# CH32F103xx register map
Vendor: WCH Ltd.; File version: 1.0
Registers are 32-bit, read-write, reset 0x0 unless marked. A register's access mark holds for its fields unless they carry their own. Offsets are from the block's base; [hi:lo] are bit positions.

## RCC — Reset and clock control
Base 0x40021000
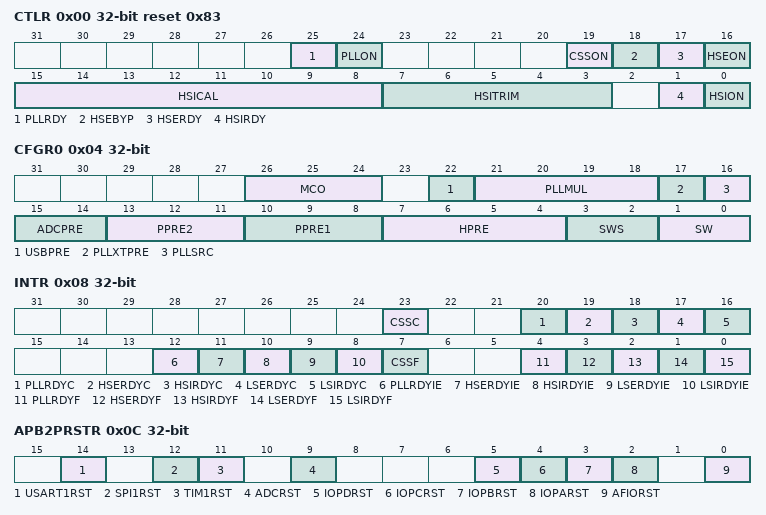
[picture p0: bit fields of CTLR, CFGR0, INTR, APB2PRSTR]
0x00 CTLR access per field reset 0x83 — Clock control register
  [25] PLLRDY ro — PLL clock ready flag
  [24] PLLON rw — PLL enable
  [19] CSSON rw — Clock Security System enable
  [18] HSEBYP rw — External High Speed clock Bypass
  [17] HSERDY ro — External High Speed clock ready flag
  [16] HSEON rw — External High Speed clock enable
  [15:8] HSICAL ro — Internal High Speed clock Calibration
  [7:3] HSITRIM rw — Internal High Speed clock trimming
  [1] HSIRDY ro — Internal High Speed clock ready flag
  [0] HSION rw — Internal High Speed clock enable
0x04 CFGR0 access per field — Clock configuration register (RCC_CFGR0)
  [26:24] MCO rw — Microcontroller clock output
  [22] USBPRE rw — USB prescaler
  [21:18] PLLMUL rw — PLL Multiplication Factor
  [17] PLLXTPRE rw — HSE divider for PLL entry
  [16] PLLSRC rw — PLL entry clock source
  [15:14] ADCPRE rw — ADC prescaler
  [13:11] PPRE2 rw — APB High speed prescaler (APB2)
  [10:8] PPRE1 rw — APB Low speed prescaler (APB1)
  [7:4] HPRE rw — AHB prescaler
  [3:2] SWS ro — System Clock Switch Status
  [1:0] SW rw — System clock Switch
0x08 INTR access per field — Clock interrupt register (RCC_INTR)
  [23] CSSC wo — Clock security system interrupt clear
  [20] PLLRDYC wo — PLL Ready Interrupt Clear
  [19] HSERDYC wo — HSE Ready Interrupt Clear
  [18] HSIRDYC wo — HSI Ready Interrupt Clear
  [17] LSERDYC wo — LSE Ready Interrupt Clear
  [16] LSIRDYC wo — LSI Ready Interrupt Clear
  [12] PLLRDYIE rw — PLL Ready Interrupt Enable
  [11] HSERDYIE rw — HSE Ready Interrupt Enable
  [10] HSIRDYIE rw — HSI Ready Interrupt Enable
  [9] LSERDYIE rw — LSE Ready Interrupt Enable
  [8] LSIRDYIE rw — LSI Ready Interrupt Enable
  [7] CSSF ro — Clock Security System Interrupt flag
  [4] PLLRDYF ro — PLL Ready Interrupt flag
  [3] HSERDYF ro — HSE Ready Interrupt flag
  [2] HSIRDYF ro — HSI Ready Interrupt flag
  [1] LSERDYF ro — LSE Ready Interrupt flag
  [0] LSIRDYF ro — LSI Ready Interrupt flag
0x0C APB2PRSTR — APB2 peripheral reset register (RCC_APB2PRSTR)
  [14] USART1RST — USART1 reset
  [12] SPI1RST — SPI 1 reset
  [11] TIM1RST — TIM1 timer reset
  [9] ADCRST — ADC interface reset
  [5] IOPDRST — IO port D reset
  [4] IOPCRST — IO port C reset
  [3] IOPBRST — IO port B reset
  [2] IOPARST — IO port A reset
  [0] AFIORST — Alternate function I/O reset
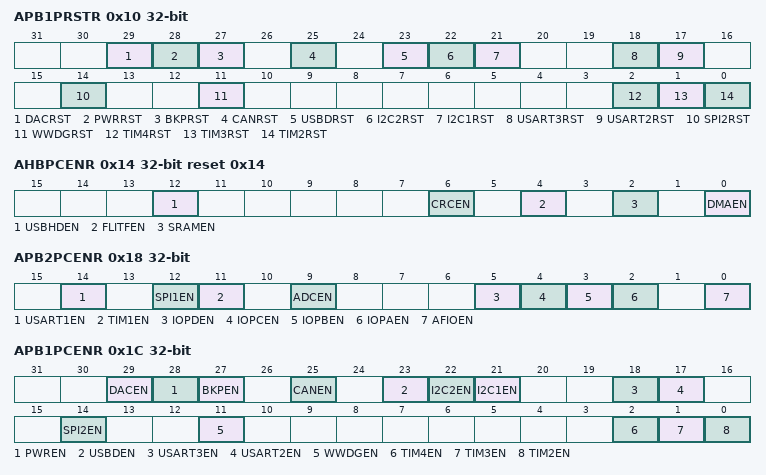
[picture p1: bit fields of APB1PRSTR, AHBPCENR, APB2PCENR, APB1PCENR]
0x10 APB1PRSTR — APB1 peripheral reset register (RCC_APB1PRSTR)
  [29] DACRST — DAC interface reset
  [28] PWRRST — Power interface reset
  [27] BKPRST — Backup interface reset
  [25] CANRST — CAN reset
  [23] USBDRST — USBD reset
  [22] I2C2RST — I2C2 reset
  [21] I2C1RST — I2C1 reset
  [18] USART3RST — USART 3 reset
  [17] USART2RST — USART 2 reset
  [14] SPI2RST — SPI2 reset
  [11] WWDGRST — Window watchdog reset
  [2] TIM4RST — Timer 4 reset
  [1] TIM3RST — Timer 3 reset
  [0] TIM2RST — Timer 2 reset
0x14 AHBPCENR reset 0x14 — AHB Peripheral Clock enable register (RCC_AHBPCENR)
  [12] USBHDEN — USBHD clock enable
  [6] CRCEN — CRC clock enable
  [4] FLITFEN — FLITF clock enable
  [2] SRAMEN — SRAM interface clock enable
  [0] DMAEN — DMA clock enable
0x18 APB2PCENR — APB2 peripheral clock enable register (RCC_APB2PCENR)
  [14] USART1EN — USART1 clock enable
  [12] SPI1EN — SPI 1 clock enable
  [11] TIM1EN — TIM1 Timer clock enable
  [9] ADCEN — ADC interface clock enable
  [5] IOPDEN — I/O port D clock enable
  [4] IOPCEN — I/O port C clock enable
  [3] IOPBEN — I/O port B clock enable
  [2] IOPAEN — I/O port A clock enable
  [0] AFIOEN — Alternate function I/O clock enable
0x1C APB1PCENR — APB1 peripheral clock enable register (RCC_APB1PCENR)
  [29] DACEN — DAC interface clock enable
  [28] PWREN — Power interface clock enable
  [27] BKPEN — Backup interface clock enable
  [25] CANEN — CAN clock enable
  [23] USBDEN — USBD clock enable
  [22] I2C2EN — I2C 2 clock enable
  [21] I2C1EN — I2C 1 clock enable
  [18] USART3EN — USART 3 clock enable
  [17] USART2EN — USART 2 clock enable
  [14] SPI2EN — SPI 2 clock enable
  [11] WWDGEN — Window watchdog clock enable
  [2] TIM4EN — Timer 4 clock enable
  [1] TIM3EN — Timer 3 clock enable
  [0] TIM2EN — Timer 2 clock enable
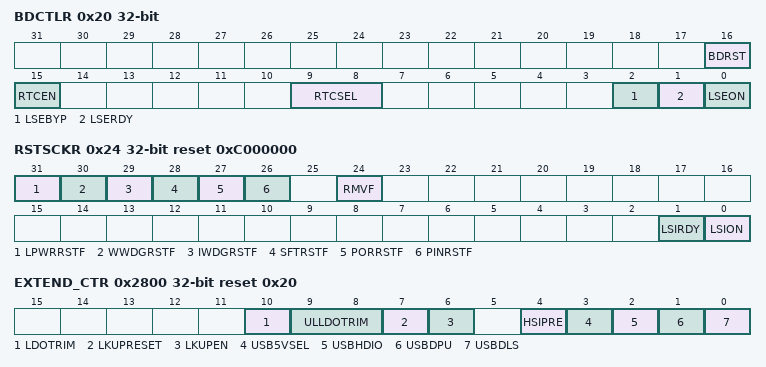
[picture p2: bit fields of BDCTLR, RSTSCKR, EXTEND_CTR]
0x20 BDCTLR access per field — Backup domain control register (RCC_BDCTLR)
  [16] BDRST rw — Backup domain software reset
  [15] RTCEN rw — RTC clock enable
  [9:8] RTCSEL rw — RTC clock source selection
  [2] LSEBYP rw — External Low Speed oscillator bypass
  [1] LSERDY ro — External Low Speed oscillator ready
  [0] LSEON rw — External Low Speed oscillator enable
0x24 RSTSCKR access per field reset 0xC000000 — Control/status register (RCC_RSTSCKR)
  [31] LPWRRSTF ro — Low-power reset flag
  [30] WWDGRSTF ro — Window watchdog reset flag
  [29] IWDGRSTF ro — Independent watchdog reset flag
  [28] SFTRSTF ro — Software reset flag
  [27] PORRSTF ro — POR/PDR reset flag
  [26] PINRSTF ro — PIN reset flag
  [24] RMVF rw — Remove reset flag
  [1] LSIRDY ro — Internal low speed oscillator ready
  [0] LSION rw — Internal low speed oscillator enable
0x28 AHBRSTR — AHB reset register (RCC_APHBRSTR)
  [12] USBHDRST — USBHD reset
0x2800 EXTEND_CTR reset 0x20 — EXTEND register
  [10] LDOTRIM
  [9:8] ULLDOTRIM
  [7] LKUPRESET — LOCKUP RESET
  [6] LKUPEN — LOCKUP
  [4] HSIPRE — Whether HSI is divided
  [3] USB5VSEL — USB 5V Enable
  [2] USBHDIO — USBHD IO(PB6/PB7) Enable
  [1] USBDPU — USBD pullup Enable
  [0] USBDLS — USBD Lowspeed Enable
